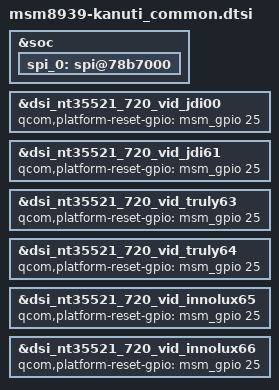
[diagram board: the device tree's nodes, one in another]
/* arch/arm/boot/dts/qcom/msm8939-kanuti_common.dtsi
 *
 * This program is free software; you can redistribute it and/or modify
 * it under the terms of the GNU General Public License version 2 and
 * only version 2 as published by the Free Software Foundation.
 *
 * This program is distributed in the hope that it will be useful,
 * but WITHOUT ANY WARRANTY; without even the implied warranty of
 * MERCHANTABILITY or FITNESS FOR A PARTICULAR PURPOSE.  See the
 * GNU General Public License for more details.
 */

/ {

};

&soc {
        spi_0: spi@78b7000 { /* BLSP1 QUP3 */
                /delete-property/ pinctrl-names;
                /delete-property/ pinctrl-0;
                /delete-property/ pinctrl-1;
	};
};

/* Panel nodes: We're using pinctrl! */
&dsi_nt35521_720_vid_jdi00 {
	qcom,platform-reset-gpio = <&msm_gpio 25 0>;
};

&dsi_nt35521_720_vid_jdi61 {
	qcom,platform-reset-gpio = <&msm_gpio 25 0>;
};

&dsi_nt35521_720_vid_truly63 {
	qcom,platform-reset-gpio = <&msm_gpio 25 0>;
};

&dsi_nt35521_720_vid_truly64 {
	qcom,platform-reset-gpio = <&msm_gpio 25 0>;
};

&dsi_nt35521_720_vid_innolux65 {
	qcom,platform-reset-gpio = <&msm_gpio 25 0>;
};

&dsi_nt35521_720_vid_innolux66 {
	qcom,platform-reset-gpio = <&msm_gpio 25 0>;
};
